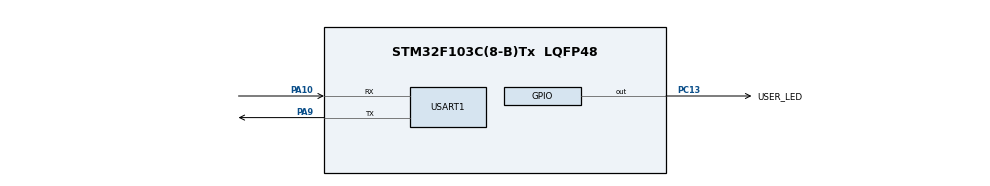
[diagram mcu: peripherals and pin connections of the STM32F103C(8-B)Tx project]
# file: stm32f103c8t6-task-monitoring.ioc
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FREERTOS.Tasks01=defaultTask,0,128,StartDefaultTask,Default,NULL,Dynamic,NULL,NULL
Mcu.Family=STM32F1
Mcu.Name=STM32F103C(8-B)Tx
Mcu.Package=LQFP48
NVIC.PriorityGroup=NVIC_PRIORITYGROUP_4
NVIC.TIM1_UP_IRQn=true\:15\:0\:false\:false\:true\:false\:false\:true\:true
NVIC.TimeBase=TIM1_UP_IRQn
NVIC.TimeBaseIP=TIM1
PA10.Mode=Asynchronous
PA10.Signal=USART1_RX
PA13.Mode=Serial_Wire
PA13.Signal=SYS_JTMS-SWDIO
PA14.Mode=Serial_Wire
PA14.Signal=SYS_JTCK-SWCLK
PA9.Mode=Asynchronous
PA9.Signal=USART1_TX
PC13-TAMPER-RTC.GPIO_Label=USER_LED
PC13-TAMPER-RTC.Signal=GPIO_Output
ProjectManager.HeapSize=0x200
ProjectManager.StackSize=0x400
ProjectManager.TargetToolchain=STM32CubeIDE
RCC.APB1Freq_Value=8000000
RCC.APB2Freq_Value=8000000
USART1.VirtualMode=VM_ASYNC
VP_FREERTOS_VS_CMSIS_V1.Mode=CMSIS_V1
VP_SYS_VS_tim1.Mode=TIM1
board=custom

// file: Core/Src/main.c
/* USER CODE BEGIN Header */
/**
  ******************************************************************************
  * @file           : main.c
  * @brief          : Main program body
  ******************************************************************************
  * @attention
  *
  * Copyright (c) 2025 STMicroelectronics.
  * All rights reserved.
  *
  * This software is licensed under terms that can be found in the LICENSE file
  * in the root directory of this software component.
  * If no LICENSE file comes with this software, it is provided AS-IS.
  *
  ******************************************************************************
  */
/* USER CODE END Header */
#include "main.h"
#include "cmsis_os.h"

/* USER CODE BEGIN Includes */
#include "stdio.h"
#include "string.h"
/* USER CODE END Includes */

/* USER CODE BEGIN PM */
#define CREATE_SERIAL_TASK (0)

/* USER CODE END PM */

UART_HandleTypeDef huart1;

osThreadId defaultTaskHandle;
/* USER CODE BEGIN PV */
osThreadId blink_task_handle;
osThreadId monitor_heap_task_handle;
osThreadId print_queue_task_handle;

/* USER CODE END PV */

void SystemClock_Config(void);
static void MX_GPIO_Init(void);
static void MX_USART1_UART_Init(void);
void StartDefaultTask(void const * argument);

/* USER CODE BEGIN PFP */

void x_task_onboard_led_blink(void const* argument);
void x_task_monitor_heap(void const* argument);
void x_task_print_to_serial(void const* argument);

/* USER CODE END PFP */

/* USER CODE BEGIN 0 */

QueueHandle_t serial_queue;

/* USER CODE END 0 */

int main(void)
{

  /* MCU Configuration--------------------------------------------------------*/

  /* Reset of all peripherals, Initializes the Flash interface and the Systick. */
  HAL_Init();

  /* Configure the system clock */
  SystemClock_Config();

  /* Initialize all configured peripherals */
  MX_GPIO_Init();
  MX_USART1_UART_Init();
  /* USER CODE BEGIN 2 */

  // get total heap size
  char t[50];
  sprintf(t, "Total heap, (using heap 4): %ul \r\n", configTOTAL_HEAP_SIZE);
  HAL_UART_Transmit(&huart1, (uint8_t*)t, strlen(t), HAL_MAX_DELAY);

  /* USER CODE END 2 */

  /* USER CODE BEGIN RTOS_QUEUES */

  serial_queue = xQueueCreate(5, sizeof(size_t));
  if(serial_queue == 0) {
	  char* str = "Serial queue not created\r\n";
	  HAL_UART_Transmit(&huart1, (uint8_t*)str, strlen(str), HAL_MAX_DELAY);
  } else {
	  char* str = "Serial queue created successfully\r\n";
	  HAL_UART_Transmit(&huart1, (uint8_t*)str, strlen(str), HAL_MAX_DELAY);
  }

  /* USER CODE END RTOS_QUEUES */

  /* Create the thread(s) */
  /* definition and creation of defaultTask */
  osThreadDef(defaultTask, StartDefaultTask, osPriorityNormal, 0, 128);
  defaultTaskHandle = osThreadCreate(osThread(defaultTask), NULL);

  /* USER CODE BEGIN RTOS_THREADS */

  osThreadDef(onboard_blink_task, x_task_onboard_led_blink, osPriorityNormal, 0, 128);
  blink_task_handle = osThreadCreate(osThread(onboard_blink_task), NULL);

  osThreadDef(monitor_heap_task, x_task_monitor_heap, osPriorityNormal, 0, 128);
  monitor_heap_task_handle = osThreadCreate(osThread(monitor_heap_task), NULL);

#if CREATE_SERIAL_TASK
  osThreadDef(print_to_serial_task, x_task_print_to_serial, osPriorityNormal, 0, 128);
  print_queue_task_handle = osThreadCreate(osThread(print_to_serial_task), NULL);
#endif

  /* USER CODE END RTOS_THREADS */

  /* Start scheduler */
  osKernelStart();

  /* We should never get here as control is now taken by the scheduler */

  /* Infinite loop */
  while (1)
  {

  }
}

void SystemClock_Config(void)
{
  RCC_OscInitTypeDef RCC_OscInitStruct = {0};
  RCC_ClkInitTypeDef RCC_ClkInitStruct = {0};

  /** Initializes the RCC Oscillators according to the specified parameters
  * in the RCC_OscInitTypeDef structure.
  */
  RCC_OscInitStruct.OscillatorType = RCC_OSCILLATORTYPE_HSI;
  RCC_OscInitStruct.HSIState = RCC_HSI_ON;
  RCC_OscInitStruct.HSICalibrationValue = RCC_HSICALIBRATION_DEFAULT;
  RCC_OscInitStruct.PLL.PLLState = RCC_PLL_NONE;
  if (HAL_RCC_OscConfig(&RCC_OscInitStruct) != HAL_OK)
  {
    Error_Handler();
  }

  /** Initializes the CPU, AHB and APB buses clocks
  */
  RCC_ClkInitStruct.ClockType = RCC_CLOCKTYPE_HCLK|RCC_CLOCKTYPE_SYSCLK
                              |RCC_CLOCKTYPE_PCLK1|RCC_CLOCKTYPE_PCLK2;
  RCC_ClkInitStruct.SYSCLKSource = RCC_SYSCLKSOURCE_HSI;
  RCC_ClkInitStruct.AHBCLKDivider = RCC_SYSCLK_DIV1;
  RCC_ClkInitStruct.APB1CLKDivider = RCC_HCLK_DIV1;
  RCC_ClkInitStruct.APB2CLKDivider = RCC_HCLK_DIV1;

  if (HAL_RCC_ClockConfig(&RCC_ClkInitStruct, FLASH_LATENCY_0) != HAL_OK)
  {
    Error_Handler();
  }
}

static void MX_USART1_UART_Init(void)
{

  huart1.Instance = USART1;
  huart1.Init.BaudRate = 115200;
  huart1.Init.WordLength = UART_WORDLENGTH_8B;
  huart1.Init.StopBits = UART_STOPBITS_1;
  huart1.Init.Parity = UART_PARITY_NONE;
  huart1.Init.Mode = UART_MODE_TX_RX;
  huart1.Init.HwFlowCtl = UART_HWCONTROL_NONE;
  huart1.Init.OverSampling = UART_OVERSAMPLING_16;
  if (HAL_UART_Init(&huart1) != HAL_OK)
  {
    Error_Handler();
  }

}

static void MX_GPIO_Init(void)
{
  GPIO_InitTypeDef GPIO_InitStruct = {0};

  /* GPIO Ports Clock Enable */
  __HAL_RCC_GPIOC_CLK_ENABLE();
  __HAL_RCC_GPIOA_CLK_ENABLE();

  /*Configure GPIO pin Output Level */
  HAL_GPIO_WritePin(USER_LED_GPIO_Port, USER_LED_Pin, GPIO_PIN_RESET);

  /*Configure GPIO pin : USER_LED_Pin */
  GPIO_InitStruct.Pin = USER_LED_Pin;
  GPIO_InitStruct.Mode = GPIO_MODE_OUTPUT_PP;
  GPIO_InitStruct.Pull = GPIO_NOPULL;
  GPIO_InitStruct.Speed = GPIO_SPEED_FREQ_LOW;
  HAL_GPIO_Init(USER_LED_GPIO_Port, &GPIO_InitStruct);

}

/* USER CODE BEGIN 4 */

void x_task_onboard_led_blink(void const* arg) {
	size_t free_heap;
	char t[20];

	for(;;) {

		free_heap = xPortGetFreeHeapSize();

		sprintf(t, "x_OL: %ul\r\n", free_heap);
		HAL_UART_Transmit(&huart1, (uint8_t*)t, strlen(t), HAL_MAX_DELAY);

		HAL_GPIO_TogglePin(USER_LED_GPIO_Port, USER_LED_Pin);
		vTaskDelay(500);
	}

}

void x_task_monitor_heap(void const* arg) {
	size_t free_heap;
	UBaseType_t high_wm; // minimum amount of stack in words that has remained since the task started
	char t[20];

	for(;;) {

		free_heap = xPortGetFreeHeapSize(); // get global free heap

		high_wm = uxTaskGetStackHighWaterMark(NULL); // null -> this task add "#define INCLUDE_uxTaskGetStackHighWaterMark   1"  in FreeRTOScONFIG.H

		//sprintf(t, "x_MH: %ul\r\n", free_heap);
		//HAL_UART_Transmit(&huart1, (uint8_t*)t, strlen(t), HAL_MAX_DELAY);

		// to calculate peak stack usage
		// this should be implemented per task and updates a stack _usage_table
		// peak usage = allocated_stack_size - (high_wm * word size)

		sprintf(t, "HighWM: %lu\r\n", high_wm);
		HAL_UART_Transmit(&huart1, (uint8_t*)t, strlen(t), HAL_MAX_DELAY);

//		if(xQueueSend(serial_queue, &free_heap, portMAX_DELAY) != pdPASS) {
//			char* str = "Could not send to queue\n\n";
//			HAL_UART_Transmit(&huart1, (uint8_t*)str, strlen(str), HAL_MAX_DELAY);
//		}

		vTaskDelay(pdMS_TO_TICKS(200));
	}
}

void x_task_print_to_serial(void const* arg) {
	size_t rcvd_free_heap;
	char m[20];

	for(;;) {

		if(xQueueReceive(serial_queue, &rcvd_free_heap, portMAX_DELAY) != pdPASS) {
			char* str = "Could not receive from queue\r\n";
			HAL_UART_Transmit(&huart1, (uint8_t*)str, strlen(str), HAL_MAX_DELAY);
		} else {
			sprintf(m, "%u\r\n", rcvd_free_heap);
			HAL_UART_Transmit(&huart1, (uint8_t*)m, strlen(m), HAL_MAX_DELAY);

		}
	}
}

/* USER CODE END 4 */

void StartDefaultTask(void const * argument)
{
  for(;;)
  {
    osDelay(1);
  }
}

void HAL_TIM_PeriodElapsedCallback(TIM_HandleTypeDef *htim)
{
  if (htim->Instance == TIM1)
  {
    HAL_IncTick();
  }
}

void Error_Handler(void)
{
  __disable_irq();
  while (1)
  {
  }
}
